VERSION ""

NS_ :

BS_:

BU_:

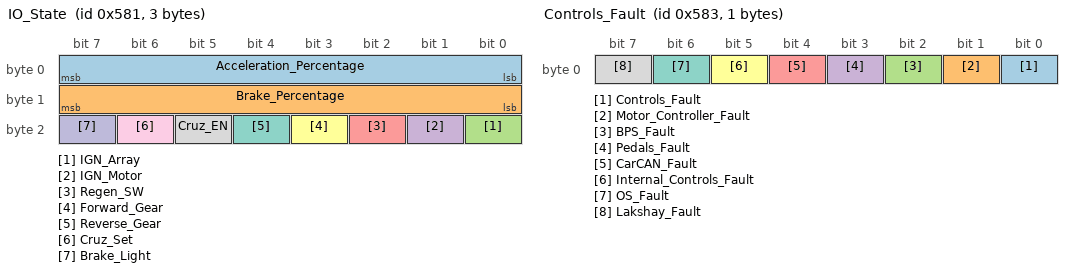
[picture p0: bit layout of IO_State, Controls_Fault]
BO_ 1409 IO_State: 3 Vector__XXX
	SG_ Acceleration_Percentage : 0|8@1+ (1,0) [0|100] "Percentage" Vector__XXX
	SG_ Brake_Percentage : 8|8@1+ (1,0) [0|100] "Percentage the brake is pressed" Vector__XXX
	SG_ IGN_Array : 16|1@1+ (1,0) [0|1] "Array Ignition On" Vector__XXX
	SG_ IGN_Motor : 17|1@1+ (1,0) [0|1] "Motor Ignition On" Vector__XXX
	SG_ Regen_SW : 18|1@1+ (1,0) [0|1] "Regen Switched On" Vector__XXX
	SG_ Forward_Gear : 19|1@1+ (1,0) [0|1] "Forward switch" Vector__XXX
	SG_ Reverse_Gear : 20|1@1+ (1,0) [0|1] "Reverse switch" Vector__XXX
	SG_ Cruz_EN : 21|1@1+ (1,0) [0|1] "Cruise Enable" Vector__XXX
	SG_ Cruz_Set : 22|1@1+ (1,0) [0|1] "Cruise Set" Vector__XXX
	SG_ Brake_Light : 23|1@1+ (1,0) [0|1] "Brakelight state" Vector__XXX

BO_ 1411 Controls_Fault: 1 Vector__XXX
	SG_ Controls_Fault : 0|1@1+ (1,0) [0|1] "" Vector__XXX
	SG_ Motor_Controller_Fault : 1|1@1+ (1,0) [0|1] "" Vector__XXX
	SG_ BPS_Fault : 2|1@1+ (1,0) [0|1] "" Vector__XXX
	SG_ Pedals_Fault : 3|1@1+ (1,0) [0|0] "" Vector__XXX
	SG_ CarCAN_Fault : 4|1@1+ (1,0) [0|1] "" Vector__XXX
	SG_ Internal_Controls_Fault : 5|1@1+ (1,0) [0|1] "" Vector__XXX
	SG_ OS_Fault : 6|1@1+ (1,0) [0|1] "" Vector__XXX
	SG_ Lakshay_Fault : 7|1@1+ (1,0) [0|1] "" Vector__XXX

BO_ 1412 Motor_Controller_Safe: 1 Vector__XXX
	SG_ Motor_Safe : 0|1@1+ (1,0) [0|1] "" Vector__XXX
	SG_ Motor_Controller_Error : 1|1@1+ (1,0) [0|1] "" Vector__XXX

BO_ 545 Motor_Drive_Command: 8 Driver
 SG_ Motor_Current_Setpoint : 32|32@1+ (1,0) [0|0] "%" Vector__XXX
 SG_ Motor_Velocity_Setpoint : 0|32@1+ (1,0) [0|0] "rpm" Vector__XXX

BO_ 546 Motor_Power_Command: 8 Driver
 SG_ Motor_Power_Setpoint : 32|32@1+ (1,0) [0|0] "%" Vector__XXX

BO_ 1413 Pedals_Raw_Voltage: 4 Vector__XXX
 SG_ Brake_Raw : 0|15@1- (1,0) [0|3300] "mV" Vector__XXX
 SG_ Accel_Raw : 16|15@1- (1,0) [0|3300] "mV" Vector__XXX

CM_ BO_ 1409 "IO State of Controls";
CM_ BO_ 1411 "Controls Fault State";
CM_ BO_ 1412 "Motor Safe State";
BA_DEF_ BO_  "VFrameFormat" ENUM  "StandardCAN","ExtendedCAN","reserved","J1939PG";
BA_DEF_  "DatabaseVersion" STRING ;
BA_DEF_  "BusType" STRING ;
BA_DEF_  "ProtocolType" STRING ;
BA_DEF_  "DatabaseCompiler" STRING ;
BA_DEF_DEF_  "VFrameFormat" "J1939PG";
BA_DEF_DEF_  "DatabaseVersion" "DEMO PLUS";
BA_DEF_DEF_  "BusType" "";
BA_DEF_DEF_  "ProtocolType" "";
BA_DEF_DEF_  "DatabaseCompiler" "";
BA_ "ProtocolType" "J1939";
BA_ "BusType" "CAN";
BA_ "DatabaseCompiler" "CSS ELECTRONICS (WWW.CSSELECTRONICS.COM)";
BA_ "DatabaseVersion" "1.0.0";

SIG_VALTYPE_ 545 Motor_Current_Setpoint : 2;
SIG_VALTYPE_ 545 Motor_Velocity_Setpoint : 2;
SIG_VALTYPE_ 546 Motor_Power_Setpoint : 2;
